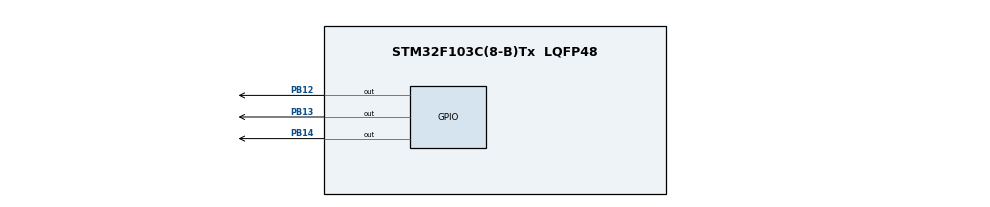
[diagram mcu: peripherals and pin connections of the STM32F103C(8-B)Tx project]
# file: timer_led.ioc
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Mcu.Family=STM32F1
Mcu.Name=STM32F103C(8-B)Tx
Mcu.Package=LQFP48
NVIC.PriorityGroup=NVIC_PRIORITYGROUP_4
NVIC.TIM1_UP_IRQn=true\:0\:0\:true\:false\:true\:true\:true\:true
PA13.Mode=Serial_Wire
PA13.Signal=SYS_JTMS-SWDIO
PA14.Mode=Serial_Wire
PA14.Signal=SYS_JTCK-SWCLK
PB12.Signal=GPIO_Output
PB13.Signal=GPIO_Output
PB14.Signal=GPIO_Output
ProjectManager.HeapSize=0x200
ProjectManager.StackSize=0x400
ProjectManager.TargetToolchain=CMake
RCC.AHBFreq_Value=8000000
RCC.APB1Freq_Value=8000000
RCC.APB1TimFreq_Value=8000000
RCC.APB2CLKDivider=RCC_HCLK_DIV16
RCC.APB2Freq_Value=500000
RCC.APB2TimFreq_Value=1000000
RCC.HCLKFreq_Value=8000000
TIM1.Period=49999
TIM1.Prescaler=0
VP_TIM1_VS_ClockSourceINT.Mode=Internal
board=custom

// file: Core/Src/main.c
/* USER CODE BEGIN Header */
/**
  ******************************************************************************
  * @file           : main.c
  * @brief          : Main program body
  ******************************************************************************
  * @attention
  *
  * Copyright (c) 2026 STMicroelectronics.
  * All rights reserved.
  *
  * This software is licensed under terms that can be found in the LICENSE file
  * in the root directory of this software component.
  * If no LICENSE file comes with this software, it is provided AS-IS.
  *
  ******************************************************************************
  */
/* USER CODE END Header */
#include "main.h"

/* USER CODE BEGIN Includes */
#include <math.h>
#include <stdint.h>

/* USER CODE END Includes */

/* USER CODE BEGIN PTD */
typedef struct {
  uint32_t pin;
  GPIO_TypeDef* port;
} led_t;

typedef struct {
  led_t* current_led;
  led_t* previous_led;
} traffic_state_t;
/* USER CODE END PTD */

/* USER CODE BEGIN PD */
#define CLK_FREQ     1  * pow(10,  6) // 1MHz
#define TIMER_PERIOD 50 * pow(10, -3) // 50 Milisecond
#define TIMER_FREQ   pow(TIMER_PERIOD, -1) // F = 1/T

#define PRESCALER 0     // (CLK_FREQ / TIMER_FREQ) / 2 - 1
#define AR_VALUE  49999 // (CLK_FREQ / TIMER_FREQ) / 2 - 1

#define GREEN_LED_PIN  GPIO_PIN_12
#define GREEN_LED_PORT GPIOB

#define YELLOW_LED_PIN  GPIO_PIN_13
#define YELLOW_LED_PORT GPIOB

#define RED_LED_PIN  GPIO_PIN_14
#define RED_LED_PORT GPIOB

/* USER CODE END PD */

TIM_HandleTypeDef htim1;

/* USER CODE BEGIN PV */

uint32_t timer_ticks = 0;

led_t green_led = {.pin = GREEN_LED_PIN, .port = GREEN_LED_PORT};
led_t yellow_led = {.pin = YELLOW_LED_PIN, .port = YELLOW_LED_PORT};
led_t red_led = {.pin = RED_LED_PIN, .port = RED_LED_PORT};
traffic_state_t traffic_state = {&green_led, &green_led};

/* USER CODE END PV */

void SystemClock_Config(void);
static void MX_GPIO_Init(void);
static void MX_TIM1_Init(void);
/* USER CODE BEGIN PFP */
void delay(uint32_t time);
void update_traffic(void);
/* USER CODE END PFP */

int main(void)
{

  /* MCU Configuration--------------------------------------------------------*/

  /* Reset of all peripherals, Initializes the Flash interface and the Systick. */
  HAL_Init();

  /* Configure the system clock */
  SystemClock_Config();

  /* Initialize all configured peripherals */
  MX_GPIO_Init();
  MX_TIM1_Init();
  /* USER CODE BEGIN 2 */
  HAL_TIM_Base_Start_IT(&htim1);

  HAL_GPIO_WritePin(traffic_state.current_led->port, traffic_state.current_led->pin, GPIO_PIN_SET);
  /* USER CODE END 2 */

  /* Infinite loop */
  /* USER CODE BEGIN WHILE */
  while (1)
  {
    update_traffic();
    /* USER CODE END WHILE */

  }
}

void SystemClock_Config(void)
{
  RCC_OscInitTypeDef RCC_OscInitStruct = {0};
  RCC_ClkInitTypeDef RCC_ClkInitStruct = {0};

  /** Initializes the RCC Oscillators according to the specified parameters
  * in the RCC_OscInitTypeDef structure.
  */
  RCC_OscInitStruct.OscillatorType = RCC_OSCILLATORTYPE_HSI;
  RCC_OscInitStruct.HSIState = RCC_HSI_ON;
  RCC_OscInitStruct.HSICalibrationValue = RCC_HSICALIBRATION_DEFAULT;
  RCC_OscInitStruct.PLL.PLLState = RCC_PLL_NONE;
  if (HAL_RCC_OscConfig(&RCC_OscInitStruct) != HAL_OK)
  {
    Error_Handler();
  }

  /** Initializes the CPU, AHB and APB buses clocks
  */
  RCC_ClkInitStruct.ClockType = RCC_CLOCKTYPE_HCLK|RCC_CLOCKTYPE_SYSCLK
                              |RCC_CLOCKTYPE_PCLK1|RCC_CLOCKTYPE_PCLK2;
  RCC_ClkInitStruct.SYSCLKSource = RCC_SYSCLKSOURCE_HSI;
  RCC_ClkInitStruct.AHBCLKDivider = RCC_SYSCLK_DIV1;
  RCC_ClkInitStruct.APB1CLKDivider = RCC_HCLK_DIV1;
  RCC_ClkInitStruct.APB2CLKDivider = RCC_HCLK_DIV16;

  if (HAL_RCC_ClockConfig(&RCC_ClkInitStruct, FLASH_LATENCY_0) != HAL_OK)
  {
    Error_Handler();
  }
}

static void MX_TIM1_Init(void)
{

  TIM_ClockConfigTypeDef sClockSourceConfig = {0};
  TIM_MasterConfigTypeDef sMasterConfig = {0};

  htim1.Instance = TIM1;
  htim1.Init.Prescaler = PRESCALER;
  htim1.Init.CounterMode = TIM_COUNTERMODE_UP;
  htim1.Init.Period = AR_VALUE;
  htim1.Init.ClockDivision = TIM_CLOCKDIVISION_DIV1;
  htim1.Init.RepetitionCounter = 0;
  htim1.Init.AutoReloadPreload = TIM_AUTORELOAD_PRELOAD_DISABLE;
  if (HAL_TIM_Base_Init(&htim1) != HAL_OK)
  {
    Error_Handler();
  }
  sClockSourceConfig.ClockSource = TIM_CLOCKSOURCE_INTERNAL;
  if (HAL_TIM_ConfigClockSource(&htim1, &sClockSourceConfig) != HAL_OK)
  {
    Error_Handler();
  }
  sMasterConfig.MasterOutputTrigger = TIM_TRGO_RESET;
  sMasterConfig.MasterSlaveMode = TIM_MASTERSLAVEMODE_DISABLE;
  if (HAL_TIMEx_MasterConfigSynchronization(&htim1, &sMasterConfig) != HAL_OK)
  {
    Error_Handler();
  }

}

static void MX_GPIO_Init(void)
{
  GPIO_InitTypeDef GPIO_InitStruct = {0};

  /* GPIO Ports Clock Enable */
  __HAL_RCC_GPIOB_CLK_ENABLE();
  __HAL_RCC_GPIOA_CLK_ENABLE();

  /*Configure GPIO pin Output Level */
  HAL_GPIO_WritePin(GPIOB, GPIO_PIN_12|GPIO_PIN_13|GPIO_PIN_14, GPIO_PIN_RESET);

  /*Configure GPIO pins : PB12 PB13 PB14 */
  GPIO_InitStruct.Pin = GPIO_PIN_12|GPIO_PIN_13|GPIO_PIN_14;
  GPIO_InitStruct.Mode = GPIO_MODE_OUTPUT_PP;
  GPIO_InitStruct.Pull = GPIO_NOPULL;
  GPIO_InitStruct.Speed = GPIO_SPEED_FREQ_LOW;
  HAL_GPIO_Init(GPIOB, &GPIO_InitStruct);

}

/* USER CODE BEGIN 4 */
void HAL_TIM_PeriodElapsedCallback(TIM_HandleTypeDef *htim){
  timer_ticks++;
}

void delay(uint32_t time){
  HAL_Delay(time);
}

void update_traffic(){

  if(timer_ticks >= 24 && traffic_state.current_led != &red_led){
    timer_ticks = 0;

    HAL_GPIO_TogglePin(traffic_state.current_led->port, traffic_state.current_led->pin);

      if(traffic_state.current_led == &green_led){
        traffic_state.current_led = &yellow_led;
      }

      else if(traffic_state.current_led == &yellow_led){
        traffic_state.current_led = &red_led;
      }

      HAL_GPIO_TogglePin(traffic_state.current_led->port, traffic_state.current_led->pin);
  } else if (timer_ticks >= 26) {
    timer_ticks = 0;

    HAL_GPIO_TogglePin(traffic_state.current_led->port, traffic_state.current_led->pin);
    traffic_state.current_led = &green_led;
    HAL_GPIO_TogglePin(traffic_state.current_led->port, traffic_state.current_led->pin);
  }

}

/* USER CODE END 4 */

void Error_Handler(void)
{
  __disable_irq();
  while (1)
  {
  }
}
